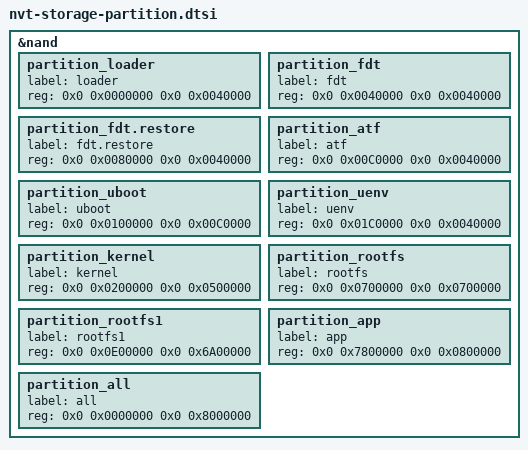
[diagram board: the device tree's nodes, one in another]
/*
 * Novatek Ltd. BSP part of dts
 */

&nand {
    partition_loader {      label = "loader";       reg = <0x0 0x0000000 0x0 0x0040000>; }; /* Fixed */
    partition_fdt {         label = "fdt";          reg = <0x0 0x0040000 0x0 0x0040000>; }; /* Fixed */
    partition_fdt.restore { label = "fdt.restore";  reg = <0x0 0x0080000 0x0 0x0040000>; }; /* Fixed */
    partition_atf {         label = "atf";          reg = <0x0 0x00C0000 0x0 0x0040000>; };
    partition_uboot {       label = "uboot";        reg = <0x0 0x0100000 0x0 0x00C0000>; };
    partition_uenv {        label = "uenv";         reg = <0x0 0x01C0000 0x0 0x0040000>; };
    partition_kernel {      label = "kernel";       reg = <0x0 0x0200000 0x0 0x0500000>; };
    partition_rootfs {      label = "rootfs";       reg = <0x0 0x0700000 0x0 0x0700000>; };
    partition_rootfs1 {     label = "rootfs1";      reg = <0x0 0x0E00000 0x0 0x6A00000>; };
    partition_app {         label = "app";          reg = <0x0 0x7800000 0x0 0x0800000>; }; /* app size depneds on hdal/samples/vendor_cfg */
    partition_all {         label = "all";          reg = <0x0 0x0000000 0x0 0x8000000>; };
};
